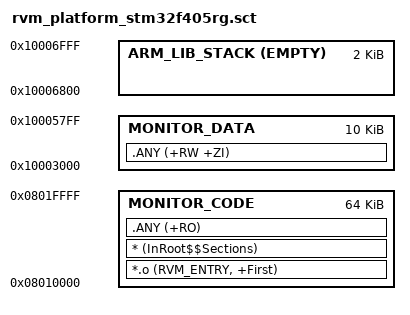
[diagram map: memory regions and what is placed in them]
;******************************************************************************
;Filename    : rvm_platform_stm32f405rg.sct
;Author      : The RVM project generator.
;Date        : 08/08/2024 16:25:25
;Licence     : Unlicense; see COPYING for details.
;Description : The scatter file for ARMv7-M layout. This file is intended
;              to be used with STM32F405RG.
;******************************************************************************

;Monitor **********************************************************************
MONITOR 0x8010000 0x10000
{
    ;Monitor code segment
    MONITOR_CODE 0x8010000 0x10000
    {
        ;The entry will be the first instruction
        *.o                    (RVM_ENTRY, +First)
        ;The lib code copying code
        *                      (InRoot$$Sections)
        ;The monitor code section
        .ANY                   (+RO)
    }

    ;Monitor data segment
    MONITOR_DATA 0x10003000 0x2800
    {
        .ANY                   (+RW +ZI)
    }

    ;Monitor stack segment - required by armlib; reusing the init thread's
    ARM_LIB_STACK 0x10006800 EMPTY 0x800
    {

    }
}
;End Monitor ******************************************************************

;End Of File ******************************************************************

;Copyright (C) Evo-Devo Instrum. All rights reserved **************************

